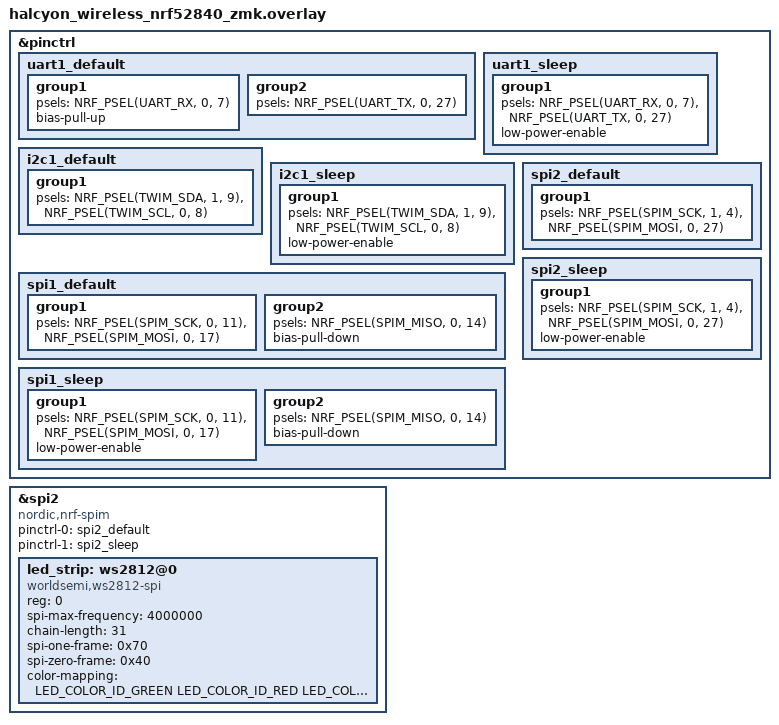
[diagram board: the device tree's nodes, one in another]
/*
 * Copyright (c) 2026 Splitkb.com
 *
 * SPDX-License-Identifier: MIT
 */

#include <dt-bindings/led/led.h>

&pinctrl {
    uart1_default: uart1_default {
        group1 {
            psels = <NRF_PSEL(UART_RX, 0, 7)>;
            bias-pull-up;
        };
        group2 {
            psels = <NRF_PSEL(UART_TX, 0, 27)>;
        };
    };

    uart1_sleep: uart1_sleep {
        group1 {
            psels = <NRF_PSEL(UART_RX, 0, 7)>,
                <NRF_PSEL(UART_TX, 0, 27)>;
            low-power-enable;
        };
    };

    i2c1_default: i2c1_default {
        group1 {
            psels = <NRF_PSEL(TWIM_SDA, 1, 9)>,
                <NRF_PSEL(TWIM_SCL, 0, 8)>;
        };
    };

    i2c1_sleep: i2c1_sleep {
        group1 {
            psels = <NRF_PSEL(TWIM_SDA, 1, 9)>,
                <NRF_PSEL(TWIM_SCL, 0, 8)>;
            low-power-enable;
        };
    };

    spi1_default: spi1_default {
        group1 {
            psels = <NRF_PSEL(SPIM_SCK, 0, 11)>,
                <NRF_PSEL(SPIM_MOSI, 0, 17)>;
        };
        group2 {
            psels = <NRF_PSEL(SPIM_MISO, 0, 14)>;
            bias-pull-down;
        };
    };

    spi1_sleep: spi1_sleep {
        group1 {
            psels = <NRF_PSEL(SPIM_SCK, 0, 11)>,
                <NRF_PSEL(SPIM_MOSI, 0, 17)>;
            low-power-enable;
        };
        group2 {
            psels = <NRF_PSEL(SPIM_MISO, 0, 14)>;
            bias-pull-down;
        };
    };

    // RGB
    spi2_default: spi2_default {
        group1 {
            psels = <NRF_PSEL(SPIM_SCK, 1, 4)>,
                    <NRF_PSEL(SPIM_MOSI, 0, 27)>;
        };
    };

    spi2_sleep: spi2_sleep {
        group1 {
            psels = <NRF_PSEL(SPIM_SCK, 1, 4)>,
                    <NRF_PSEL(SPIM_MOSI, 0, 27)>;
            low-power-enable;
        };
    };
};

//RGB
&spi2 {
    compatible = "nordic,nrf-spim";
    status = "okay";

    pinctrl-0 = <&spi2_default>;
    pinctrl-1 = <&spi2_sleep>;
    pinctrl-names = "default", "sleep";

    led_strip: ws2812@0 {
        compatible = "worldsemi,ws2812-spi";

        /* SPI */
        reg = <0>; /* ignored, but necessary for SPI bindings */
        spi-max-frequency = <4000000>;

        /* WS2812 */
        chain-length = <31>; /* arbitrary; change at will */
        spi-one-frame = <0x70>;
        spi-zero-frame = <0x40>;

        color-mapping = <LED_COLOR_ID_GREEN 
                LED_COLOR_ID_RED 
                LED_COLOR_ID_BLUE>;
    };
};
